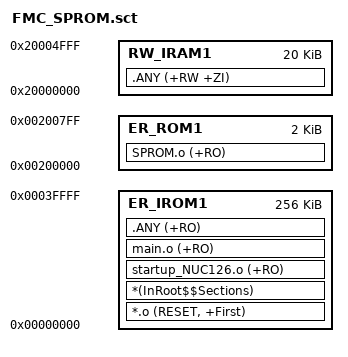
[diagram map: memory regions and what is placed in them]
LR_IROM1 0x00000000 0x00040000  {
  ER_IROM1 0x00000000 0x00040000  {
   *.o (RESET, +First)
   *(InRoot$$Sections)
    startup_NUC126.o (+RO) 
    main.o (+RO)
   .ANY (+RO)
  }
  RW_IRAM1 0x20000000 0x00005000  {
   .ANY (+RW +ZI)
  }
}

LR_ROM1 0x00200000 0x00000800  {
  ER_ROM1 0x00200000 0x00000800  {
    SPROM.o (+RO)
  }
}
